# A5PSW register map
Registers from a debugger description file.
Registers are 32-bit, read-only, no defined reset value unless marked. A register's access mark holds for its fields unless they carry their own. Addresses are absolute; registers are grouped by the start of their names; lines under a group give offsets from that group; [hi:lo] are bit positions; {n}, {i} and the like mark numbered series; 'fields as' and 'values as' point back to an identical list; <NAME> marks a mode.

## A5PSW
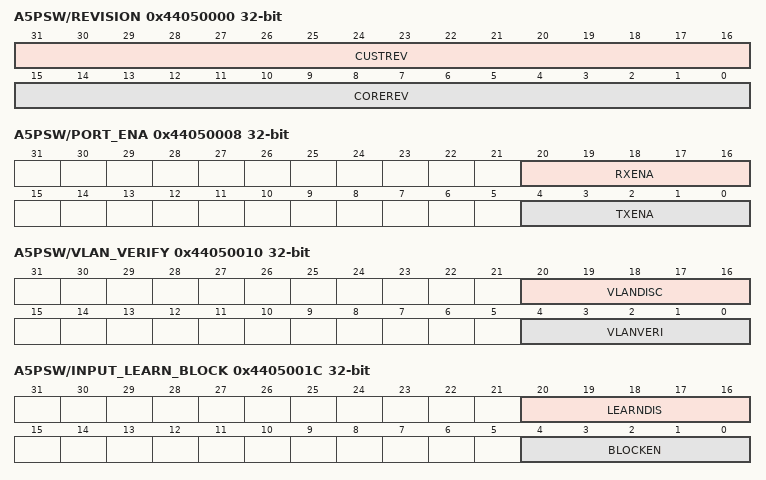
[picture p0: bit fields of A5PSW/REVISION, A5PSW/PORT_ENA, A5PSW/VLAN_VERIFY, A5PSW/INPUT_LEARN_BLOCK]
0x44050000 A5PSW/REVISION
  [31:16] CUSTREV, [15:0] COREREV
0x44050004 A5PSW/SCRATCH access not given
0x44050008 A5PSW/PORT_ENA access not given
  [20:16] RXENA, [4:0] TXENA
0x4405000C A5PSW/UCAST_DEFAULT_MASK access not given
  [4:0] UCASTDM
0x44050010 A5PSW/VLAN_VERIFY access not given
  [20:16] VLANDISC, [4:0] VLANVERI
0x44050014 A5PSW/BCAST_DEFAULT_MASK access not given
  [4:0] BCASTDM
0x44050018 A5PSW/MCAST_DEFAULT_MASK access not given
  [4:0] MCASTDM
0x4405001C A5PSW/INPUT_LEARN_BLOCK access not given
  [20:16] LEARNDIS, [4:0] BLOCKEN
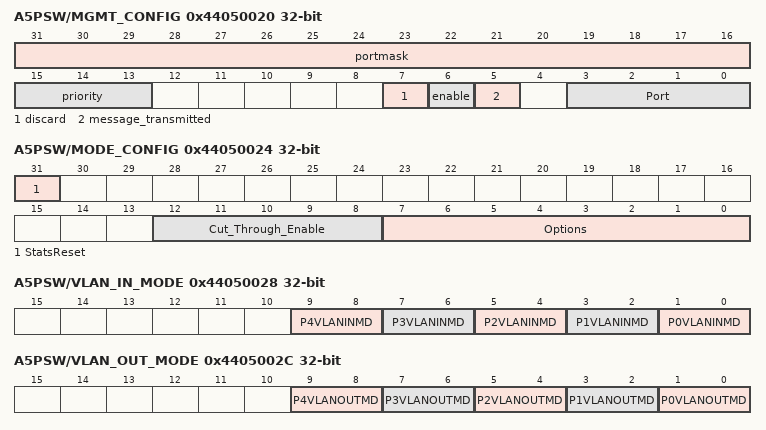
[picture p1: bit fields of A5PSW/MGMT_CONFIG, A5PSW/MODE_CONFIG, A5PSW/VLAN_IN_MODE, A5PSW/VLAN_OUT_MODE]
0x44050020 A5PSW/MGMT_CONFIG access not given
  [31:16] portmask, [15:13] priority, [7] discard, [6] enable, [5] message_transmitted, [3:0] Port
0x44050024 A5PSW/MODE_CONFIG access not given
  [31] StatsReset, [12:8] Cut_Through_Enable, [7:0] Options
0x44050028 A5PSW/VLAN_IN_MODE access not given
  [2n+1:2n] P{n}VLANINMD (n=0..4)
0x4405002C A5PSW/VLAN_OUT_MODE access not given
  [2n+1:2n] P{n}VLANOUTMD (n=0..4)
0x44050030 A5PSW/VLAN_IN_MODE_ENA access not given
  [4:0] VLANINMDEN
0x44050034 A5PSW/VLAN_TAG_ID
  [15:0] VLANTAGID
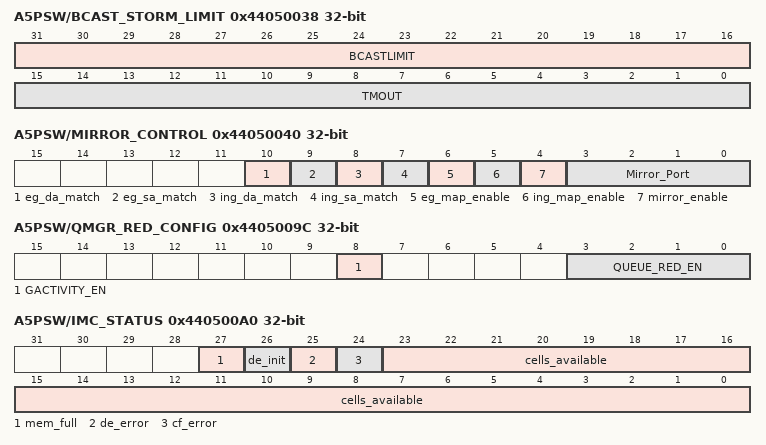
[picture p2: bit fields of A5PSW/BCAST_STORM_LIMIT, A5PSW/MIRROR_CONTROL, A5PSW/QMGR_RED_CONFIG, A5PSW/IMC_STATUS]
0x44050038 A5PSW/BCAST_STORM_LIMIT access not given
  [31:16] BCASTLIMIT, [15:0] TMOUT
0x4405003C A5PSW/MCAST_STORM_LIMIT access not given
  [31:16] MCASTLIMIT
0x44050040 A5PSW/MIRROR_CONTROL access not given
  [10] eg_da_match, [9] eg_sa_match, [8] ing_da_match, [7] ing_sa_match, [6] eg_map_enable, [5] ing_map_enable, [4] mirror_enable, [3:0] Mirror_Port
0x44050044 A5PSW/MIRROR_EG_MAP access not given
  [4:0] EMAP
0x44050048 A5PSW/MIRROR_ING_MAP access not given
  [4:0] IMAP
0x4405004C A5PSW/MIRROR_ISRC_0 access not given
  [31:0] ISRC
0x44050050 A5PSW/MIRROR_ISRC_1 access not given
  [15:0] ISRC
0x44050054 A5PSW/MIRROR_IDST_0 access not given
  [31:0] IDST
0x44050058 A5PSW/MIRROR_IDST_1 access not given
  [15:0] IDST
0x4405005C A5PSW/MIRROR_ESRC_0 access not given
  [31:0] ESRC
0x44050060 A5PSW/MIRROR_ESRC_1 access not given
  [15:0] ESRC
0x44050064 A5PSW/MIRROR_EDST_0 access not given
  [31:0] EDST
0x44050068 A5PSW/MIRROR_EDST_1 access not given
  [15:0] EDST
0x4405006C A5PSW/MIRROR_CNT access not given
  [7:0] CNT
0x44050088 A5PSW/QMGR_ST_MINCELLS access not given
  [10:0] M_CELLS_MIN
0x44050094 A5PSW/QMGR_RED_MIN4 access not given
  [31:0] CFGRED_MINTH4
0x44050098 A5PSW/QMGR_RED_MAX4 access not given
  [31:0] CFGRED_MAXTH4
0x4405009C A5PSW/QMGR_RED_CONFIG access not given
  [8] GACTIVITY_EN, [3:0] QUEUE_RED_EN
0x440500A0 A5PSW/IMC_STATUS
  [27] mem_full, [26] de_init, [25] de_error, [24] cf_error, [23:0] cells_available
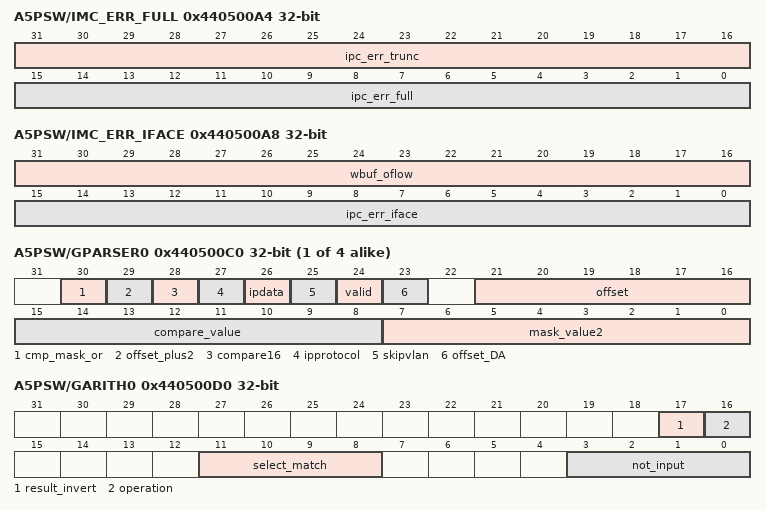
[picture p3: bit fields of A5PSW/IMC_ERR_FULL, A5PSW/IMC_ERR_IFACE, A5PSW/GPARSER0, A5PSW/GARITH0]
0x440500A4 A5PSW/IMC_ERR_FULL
  [31:16] ipc_err_trunc, [15:0] ipc_err_full
0x440500A8 A5PSW/IMC_ERR_IFACE
  [31:16] wbuf_oflow, [15:0] ipc_err_iface
0x440500AC A5PSW/IMC_ERR_QOFLOW
  [15:0] op_error
0x440500B0 A5PSW/IMC_CONFIG access not given
  [0] wfq_enable
{0x440500C0+4i} A5PSW/GPARSER{i} access not given (i=0..3)
  [30] cmp_mask_or, [29] offset_plus2, [28] compare16, [27] ipprotocol, [26] ipdata, [25] skipvlan, [24] valid, [23] offset_DA, [21:16] offset, [15:8] compare_value, [7:0] mask_value2
0x440500D0 A5PSW/GARITH0 access not given
  [17] result_invert, [16] operation, [11:8] select_match, [3:0] not_input
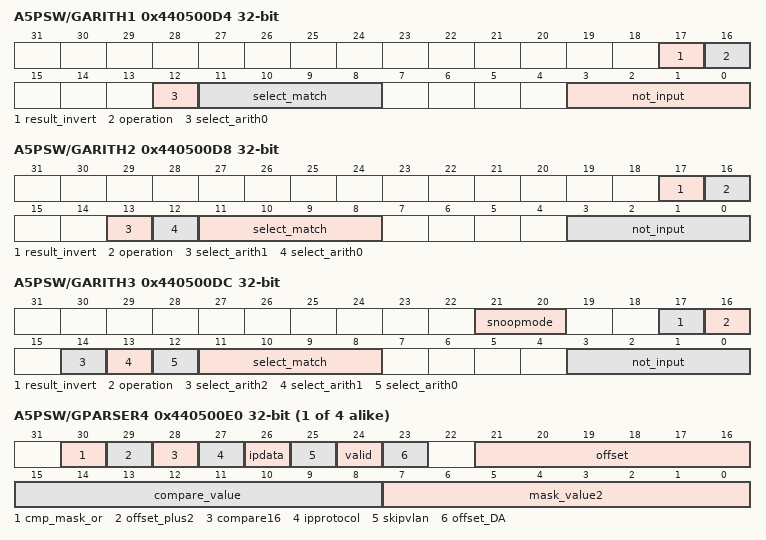
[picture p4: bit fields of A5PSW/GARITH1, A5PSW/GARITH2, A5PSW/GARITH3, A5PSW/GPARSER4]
0x440500D4 A5PSW/GARITH1 access not given
  [17] result_invert, [16] operation, [12] select_arith0, [11:8] select_match, [3:0] not_input
0x440500D8 A5PSW/GARITH2 access not given
  [17] result_invert, [16] operation, [13] select_arith1, [12] select_arith0, [11:8] select_match, [3:0] not_input
0x440500DC A5PSW/GARITH3 access not given
  [21:20] snoopmode, [17] result_invert, [16] operation, [14] select_arith2, [13] select_arith1, [12] select_arith0, [11:8] select_match, [3:0] not_input
{0x440500D0+4i} A5PSW/GPARSER{i} access not given (i=4..7)
  fields as A5PSW/GPARSER0
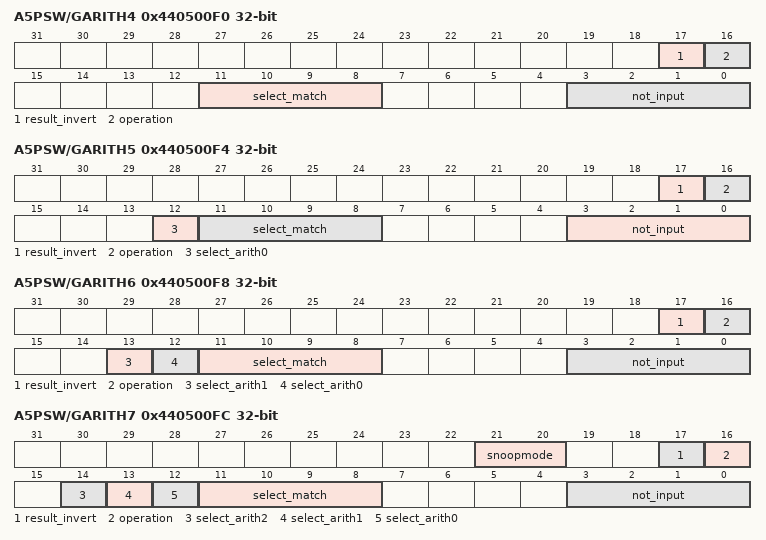
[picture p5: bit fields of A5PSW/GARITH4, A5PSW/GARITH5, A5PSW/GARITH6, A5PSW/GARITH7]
0x440500F0 A5PSW/GARITH4 access not given
  fields as A5PSW/GARITH0
0x440500F4 A5PSW/GARITH5 access not given
  fields as A5PSW/GARITH1
0x440500F8 A5PSW/GARITH6 access not given
  fields as A5PSW/GARITH2
0x440500FC A5PSW/GARITH7 access not given
  fields as A5PSW/GARITH3
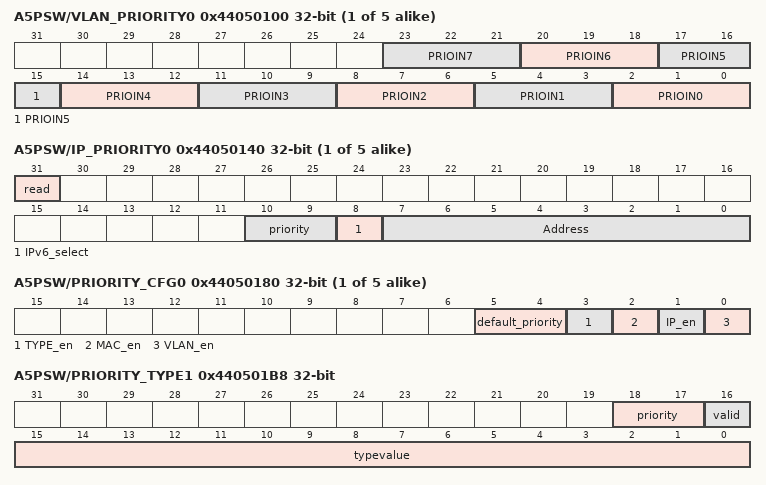
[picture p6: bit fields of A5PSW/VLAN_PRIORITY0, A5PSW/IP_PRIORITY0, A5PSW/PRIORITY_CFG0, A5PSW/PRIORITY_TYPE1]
{0x44050100+4i} A5PSW/VLAN_PRIORITY{i} access not given (i=0..4)
  [3n+2:3n] PRIOIN{n} (n=0..7)
{0x44050140+4i} A5PSW/IP_PRIORITY{i} access not given (i=0..4)
  [31] read, [10:9] priority, [8] IPv6_select, [7:0] Address
{0x44050180+4i} A5PSW/PRIORITY_CFG{i} access not given (i=0..4)
  [5:4] default_priority, [3] TYPE_en, [2] MAC_en, [1] IP_en, [0] VLAN_en
0x440501B8 A5PSW/PRIORITY_TYPE1 access not given
  [18:17] priority, [16] valid, [15:0] typevalue
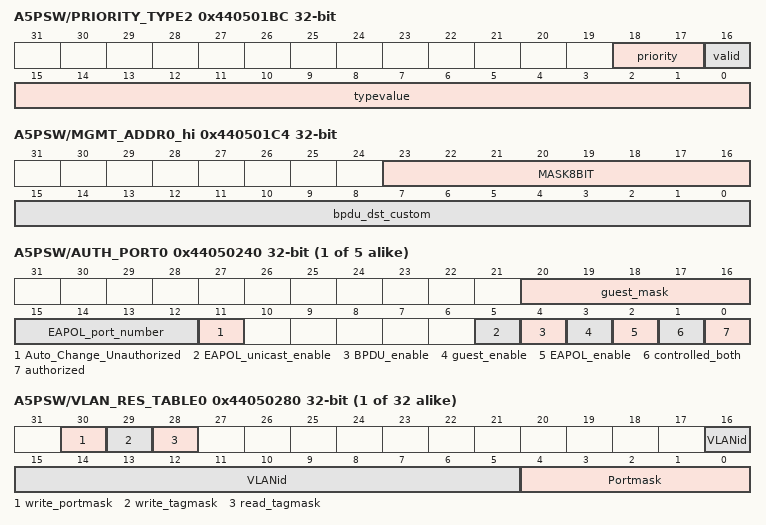
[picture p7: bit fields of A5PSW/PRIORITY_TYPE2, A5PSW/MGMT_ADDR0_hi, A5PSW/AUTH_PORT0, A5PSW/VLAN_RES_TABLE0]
0x440501BC A5PSW/PRIORITY_TYPE2 access not given
  [18:17] priority, [16] valid, [15:0] typevalue
0x440501C0 A5PSW/MGMT_ADDR0_lo access not given
  [31:0] bpdu_dst_custom
0x440501C4 A5PSW/MGMT_ADDR0_hi access not given
  [23:16] MASK8BIT, [15:0] bpdu_dst_custom
{0x44050200+4i} A5PSW/SYSTEM_TAGINFO{i} access not given (i=0..4)
  [15:0] SYSVLANINFO
{0x44050240+4i} A5PSW/AUTH_PORT{i} access not given (i=0..4)
  [20:16] guest_mask, [15:12] EAPOL_port_number, [11] Auto_Change_Unauthorized, [5] EAPOL_unicast_enable, [4] BPDU_enable, [3] guest_enable, [2] EAPOL_enable, [1] controlled_both, [0] authorized
{0x44050280+4i} A5PSW/VLAN_RES_TABLE{i} access not given (i=0..31)
  [30] write_portmask, [29] write_tagmask, [28] read_tagmask, [16:5] VLANid, [4:0] Portmask
0x44050300 A5PSW/TOTAL_DISC
0x44050304 A5PSW/TOTAL_BYT_DISC
0x44050308 A5PSW/TOTAL_FRM
0x4405030C A5PSW/TOTAL_BYT_FRM
{0x44050310+0x10*i} A5PSW/ODISC{i} (i=0..4)
{0x44050314+0x10*i} A5PSW/IDISC_VLAN{i} (i=0..4)
{0x44050318+0x10*i} A5PSW/IDISC_UNTAGGED{i} (i=0..4)
{0x4405031C+0x10*i} A5PSW/IDISC_BLOCKED{i} (i=0..4)
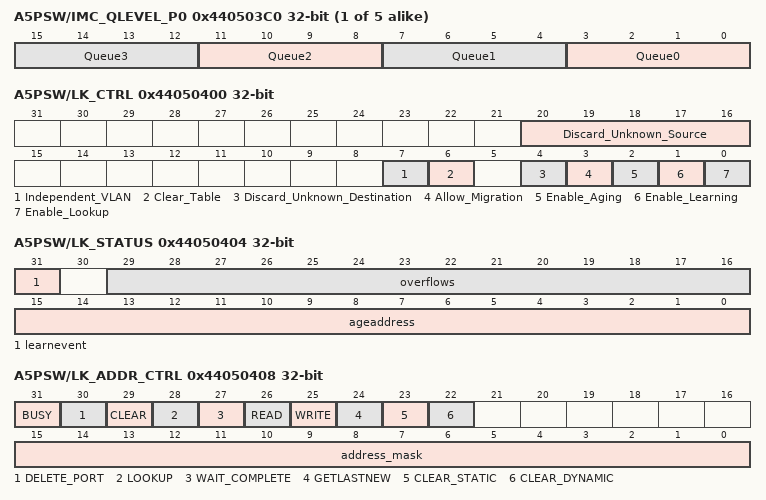
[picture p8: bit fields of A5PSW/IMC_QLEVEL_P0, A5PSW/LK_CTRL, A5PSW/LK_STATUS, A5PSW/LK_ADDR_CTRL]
{0x440503C0+4i} A5PSW/IMC_QLEVEL_P{i} (i=0..4)
  [4n+3:4n] Queue{n} (n=0..3)
0x44050400 A5PSW/LK_CTRL access not given
  [20:16] Discard_Unknown_Source, [7] Independent_VLAN, [6] Clear_Table, [4] Discard_Unknown_Destination, [3] Allow_Migration, [2] Enable_Aging, [1] Enable_Learning, [0] Enable_Lookup
0x44050404 A5PSW/LK_STATUS access not given
  [31] learnevent, [29:16] overflows, [15:0] ageaddress
0x44050408 A5PSW/LK_ADDR_CTRL access not given
  [31] BUSY, [30] DELETE_PORT, [29] CLEAR, [28] LOOKUP, [27] WAIT_COMPLETE, [26] READ, [25] WRITE, [24] GETLASTNEW, [23] CLEAR_STATIC, [22] CLEAR_DYNAMIC, [15:0] address_mask
0x4405040C A5PSW/LK_DATA_LO access not given
  [31:0] MEMDATA
0x44050410 A5PSW/LK_DATA_HI access not given
  [31:0] MEMDATA
0x44050414 A5PSW/LK_DATA_HI2 access not given
  [4:0] MEMDATA
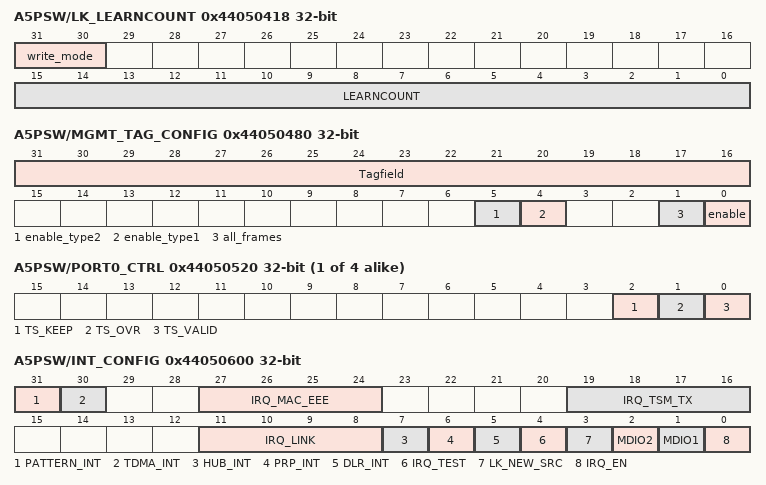
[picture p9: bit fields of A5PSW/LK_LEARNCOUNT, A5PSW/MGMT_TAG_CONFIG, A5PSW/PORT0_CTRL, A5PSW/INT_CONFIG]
0x44050418 A5PSW/LK_LEARNCOUNT access not given
  [31:30] write_mode, [15:0] LEARNCOUNT
0x4405041C A5PSW/LK_AGETIME access not given
  [23:0] LK_AGETIME
0x44050480 A5PSW/MGMT_TAG_CONFIG access not given
  [31:16] Tagfield, [5] enable_type2, [4] enable_type1, [1] all_frames, [0] enable
{0x4405050C+4i} A5PSW/PEERDELAY{i} access not given (i=0..3)
  [29:0] PEERDELAY{i}
{0x44050520+8i} A5PSW/PORT{i}_CTRL access not given (i=0..3)
  [2] TS_KEEP, [1] TS_OVR, [0] TS_VALID
{0x44050524+8i} A5PSW/PORT{i}_TIME (i=0..3)
0x44050600 A5PSW/INT_CONFIG access not given
  [31] PATTERN_INT, [30] TDMA_INT, [27:24] IRQ_MAC_EEE, [19:16] IRQ_TSM_TX, [11:8] IRQ_LINK, [7] HUB_INT, [6] PRP_INT, [5] DLR_INT, [4] IRQ_TEST, [3] LK_NEW_SRC, [2] MDIO2, [1] MDIO1, [0] IRQ_EN
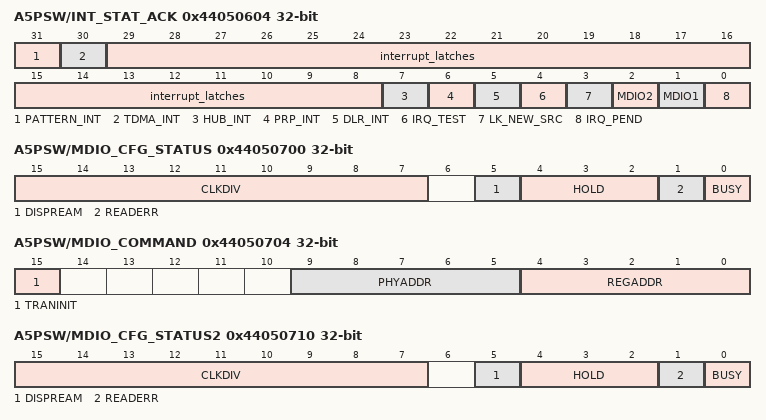
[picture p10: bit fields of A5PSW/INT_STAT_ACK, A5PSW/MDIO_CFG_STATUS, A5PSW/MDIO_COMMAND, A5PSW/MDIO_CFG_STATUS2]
0x44050604 A5PSW/INT_STAT_ACK access not given
  [31] PATTERN_INT, [30] TDMA_INT, [29:8] interrupt_latches, [7] HUB_INT, [6] PRP_INT, [5] DLR_INT, [4] IRQ_TEST, [3] LK_NEW_SRC, [2] MDIO2, [1] MDIO1, [0] IRQ_PEND
0x44050700 A5PSW/MDIO_CFG_STATUS access not given
  [15:7] CLKDIV, [5] DISPREAM, [4:2] HOLD, [1] READERR, [0] BUSY
0x44050704 A5PSW/MDIO_COMMAND access not given
  [15] TRANINIT, [9:5] PHYADDR, [4:0] REGADDR
0x44050708 A5PSW/MDIO_DATA access not given
  [15:0] MDIO_DATA
0x44050710 A5PSW/MDIO_CFG_STATUS2 access not given
  [15:7] CLKDIV, [5] DISPREAM, [4:2] HOLD, [1] READERR, [0] BUSY
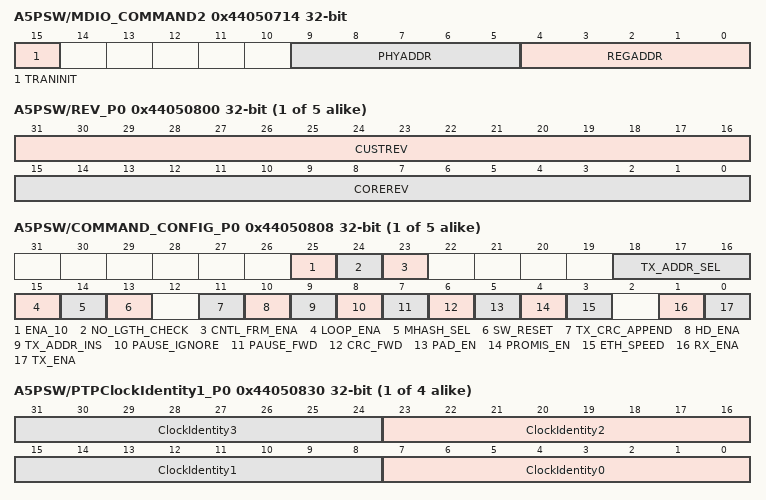
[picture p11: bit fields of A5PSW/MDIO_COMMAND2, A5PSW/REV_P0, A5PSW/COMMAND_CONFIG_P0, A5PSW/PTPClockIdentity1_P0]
0x44050714 A5PSW/MDIO_COMMAND2 access not given
  [15] TRANINIT, [9:5] PHYADDR, [4:0] REGADDR
0x44050718 A5PSW/MDIO_DATA2 access not given
  [15:0] MDIO_DATA
{0x44050800+0x400*i} A5PSW/REV_P{i} (i=0..4)
  [31:16] CUSTREV, [15:0] COREREV
{0x44050808+0x400*i} A5PSW/COMMAND_CONFIG_P{i} access not given (i=0..4)
  [25] ENA_10, [24] NO_LGTH_CHECK, [23] CNTL_FRM_ENA, [18:16] TX_ADDR_SEL, [15] LOOP_ENA, [14] MHASH_SEL, [13] SW_RESET, [11] TX_CRC_APPEND, [10] HD_ENA, [9] TX_ADDR_INS, [8] PAUSE_IGNORE, [7] PAUSE_FWD, [6] CRC_FWD, [5] PAD_EN, [4] PROMIS_EN, [3] ETH_SPEED, [1] RX_ENA, [0] TX_ENA
{0x4405080C+0x400*i} A5PSW/MAC_ADDR_0_P{i} access not given (i=0..3)
  [31:0] MAC_ADDR
{0x44050810+0x400*i} A5PSW/MAC_ADDR_1_P{i} access not given (i=0..3)
  [15:0] MAC_ADDR
{0x44050814+0x400*i} A5PSW/FRM_LENGTH_P{i} access not given (i=0..4)
  [13:0] FRM_LENGTH
{0x44050818+0x400*i} A5PSW/PAUSE_QUANT_P{i} access not given (i=0..4)
  [15:0] PAUSE_QUANT
{0x44050830+0x400*i} A5PSW/PTPClockIdentity1_P{i} access not given (i=0..3)
  [8n+7:8n] ClockIdentity{n} (n=0..3)
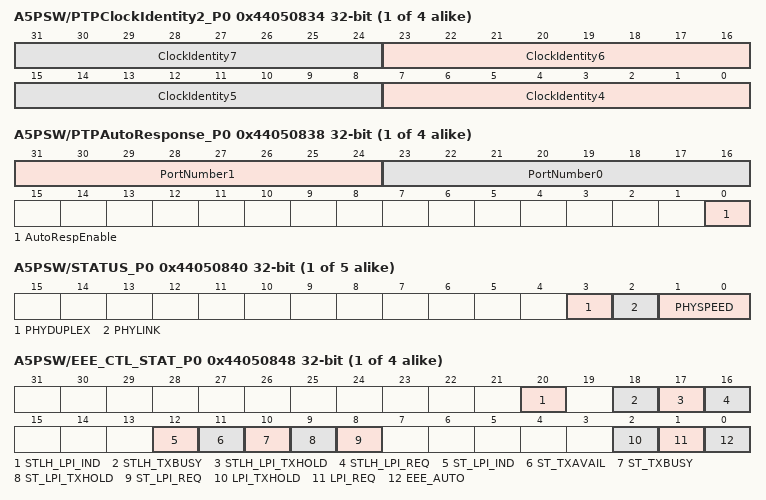
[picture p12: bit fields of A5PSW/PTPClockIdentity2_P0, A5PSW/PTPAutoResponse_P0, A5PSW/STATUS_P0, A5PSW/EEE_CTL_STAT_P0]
{0x44050834+0x400*i} A5PSW/PTPClockIdentity2_P{i} access not given (i=0..3)
  [8n-25:8n-32] ClockIdentity{n} (n=4..7)
{0x44050838+0x400*i} A5PSW/PTPAutoResponse_P{i} access not given (i=0..3)
  [31:24] PortNumber1, [23:16] PortNumber0, [0] AutoRespEnable
{0x44050840+0x400*i} A5PSW/STATUS_P{i} (i=0..4)
  [3] PHYDUPLEX, [2] PHYLINK, [1:0] PHYSPEED
{0x44050844+0x400*i} A5PSW/TX_IPG_LENGTH_P{i} access not given (i=0..4)
  [4:0] TX_IPG_LENGTH
{0x44050848+0x400*i} A5PSW/EEE_CTL_STAT_P{i} (i=0..3)
  [20] STLH_LPI_IND, [18] STLH_TXBUSY, [17] STLH_LPI_TXHOLD, [16] STLH_LPI_REQ, [12] ST_LPI_IND, [11] ST_TXAVAIL, [10] ST_TXBUSY, [9] ST_LPI_TXHOLD, [8] ST_LPI_REQ, [2] LPI_TXHOLD, [1] LPI_REQ, [0] EEE_AUTO
{0x4405084C+0x400*i} A5PSW/EEE_IDLE_TIME_P{i} access not given (i=0..3)
{0x44050850+0x400*i} A5PSW/EEE_TWSYS_TIME_P{i} access not given (i=0..3)
{0x44050854+0x400*i} A5PSW/IDLE_SLOPE_P{i} access not given (i=0..4)
  [10:0] IDLE_SLOPE
{0x44050868+0x400*i} A5PSW/aFramesTransmittedOK_P{i} (i=0..4)
{0x4405086C+0x400*i} A5PSW/aFramesReceivedOK_P{i} (i=0..4)
{0x44050870+0x400*i} A5PSW/aFrameCheckSequenceErrors_P{i} (i=0..4)
{0x44050874+0x400*i} A5PSW/aAlignmentErrors_P{i} (i=0..4)
{0x44050878+0x400*i} A5PSW/aOctetsTransmittedOK_P{i} (i=0..4)
{0x4405087C+0x400*i} A5PSW/aOctetsReceivedOK_P{i} (i=0..4)
{0x44050880+0x400*i} A5PSW/aTxPAUSEMACCtrlFrames_P{i} (i=0..4)
{0x44050884+0x400*i} A5PSW/aRxPAUSEMACCtrlFrames_P{i} (i=0..4)
{0x44050888+0x400*i} A5PSW/ifInErrors_P{i} (i=0..4)
{0x4405088C+0x400*i} A5PSW/ifOutErrors_P{i} (i=0..4)
{0x44050890+0x400*i} A5PSW/ifInUcastPkts_P{i} (i=0..4)
{0x44050894+0x400*i} A5PSW/ifInMulticastPkts_P{i} (i=0..4)
{0x44050898+0x400*i} A5PSW/ifInBroadcastPkts_P{i} (i=0..4)
{0x4405089C+0x400*i} A5PSW/ifOutDiscards_P{i} (i=0..4)
{0x440508A0+0x400*i} A5PSW/ifOutUcastPkts_P{i} (i=0..4)
{0x440508A4+0x400*i} A5PSW/ifOutMulticastPkts_P{i} (i=0..4)
{0x440508A8+0x400*i} A5PSW/ifOutBroadcastPkts_P{i} (i=0..4)
{0x440508AC+0x400*i} A5PSW/etherStatsDropEvents_P{i} (i=0..4)
{0x440508B0+0x400*i} A5PSW/etherStatsOctets_P{i} (i=0..4)
{0x440508B4+0x400*i} A5PSW/etherStatsPkts_P{i} (i=0..4)
{0x440508B8+0x400*i} A5PSW/etherStatsUndersizePkts_P{i} (i=0..4)
{0x440508BC+0x400*i} A5PSW/etherStatsOversizePkts_P{i} (i=0..4)
{0x440508C0+0x400*i} A5PSW/etherStatsPkts64Octets_P{i} (i=0..4)
{0x440508C4+0x400*i} A5PSW/etherStatsPkts65to127Octets_P{i} (i=0..4)
{0x440508C8+0x400*i} A5PSW/etherStatsPkts128to255Octets_P{i} (i=0..4)
{0x440508CC+0x400*i} A5PSW/etherStatsPkts256to511Octets_P{i} (i=0..4)
{0x440508D0+0x400*i} A5PSW/etherStatsPkts512to1023Octets_P{i} (i=0..4)
{0x440508D4+0x400*i} A5PSW/etherStatsPkts1024to1518Octets_P{i} (i=0..4)
{0x440508D8+0x400*i} A5PSW/etherStatsPkts1519toXOctets_P{i} (i=0..4)
{0x440508DC+0x400*i} A5PSW/etherStatsJabbers_P{i} (i=0..4)
{0x440508E0+0x400*i} A5PSW/etherStatsFragments_P{i} (i=0..4)
{0x440508E8+0x400*i} A5PSW/VLANReceivedOK_P{i} (i=0..4)
{0x440508F4+0x400*i} A5PSW/VLANTransmittedOK_P{i} (i=0..4)
{0x440508F8+0x400*i} A5PSW/FramesRetransmitted_P{i} (i=0..4)
{0x44050900+0x400*i} A5PSW/STATS_HIWORD_P{i} (i=0..4)
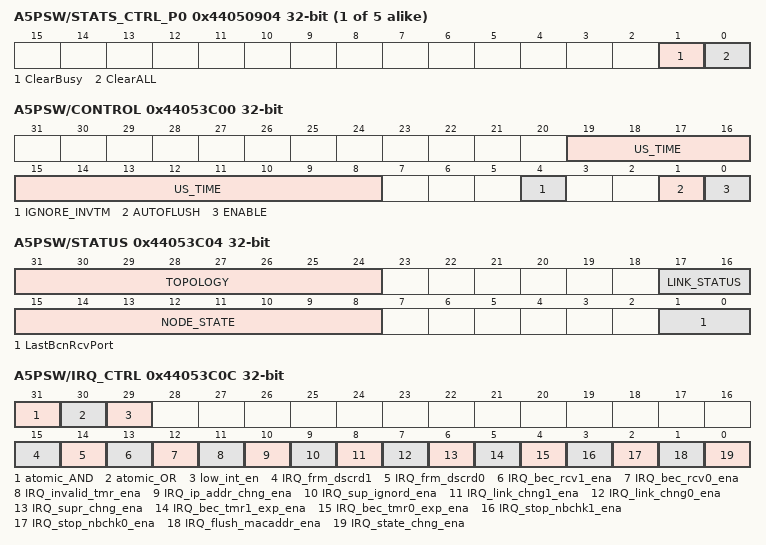
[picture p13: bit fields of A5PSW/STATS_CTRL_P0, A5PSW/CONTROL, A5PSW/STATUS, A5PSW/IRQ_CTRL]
{0x44050904+0x400*i} A5PSW/STATS_CTRL_P{i} access not given (i=0..4)
  [1] ClearBusy, [0] ClearALL
{0x44050908+0x400*i} A5PSW/STATS_CLEAR_VALUELO_P{i} (i=0..4)
{0x4405090C+0x400*i} A5PSW/STATS_CLEAR_VALUEHI_P{i} (i=0..4)
{0x44050910+0x400*i} A5PSW/aDeferred_P{i} (i=0..4)
{0x44050914+0x400*i} A5PSW/aMultipleCollisions_P{i} (i=0..4)
{0x44050918+0x400*i} A5PSW/aSingleCollisions_P{i} (i=0..4)
{0x4405091C+0x400*i} A5PSW/aLateCollisions_P{i} (i=0..4)
{0x44050920+0x400*i} A5PSW/aExcessiveCollisions_P{i} (i=0..4)
{0x44050924+0x400*i} A5PSW/aCarrierSenseErrors_P{i} (i=0..4)
0x44053C00 A5PSW/CONTROL access not given
  [19:8] US_TIME, [4] IGNORE_INVTM, [1] AUTOFLUSH, [0] ENABLE
0x44053C04 A5PSW/STATUS
  [31:24] TOPOLOGY, [17:16] LINK_STATUS, [15:8] NODE_STATE, [1:0] LastBcnRcvPort
0x44053C08 A5PSW/DLR_ETH_TYP access not given
  [15:0] DLR_ETH_TYP
0x44053C0C A5PSW/IRQ_CTRL access not given
  [31] atomic_AND, [30] atomic_OR, [29] low_int_en, [15] IRQ_frm_dscrd1, [14] IRQ_frm_dscrd0, [13] IRQ_bec_rcv1_ena, [12] IRQ_bec_rcv0_ena, [11] IRQ_invalid_tmr_ena, [10] IRQ_ip_addr_chng_ena, [9] IRQ_sup_ignord_ena, [8] IRQ_link_chng1_ena, [7] IRQ_link_chng0_ena, [6] IRQ_supr_chng_ena, [5] IRQ_bec_tmr1_exp_ena, [4] IRQ_bec_tmr0_exp_ena, [3] IRQ_stop_nbchk1_ena, [2] IRQ_stop_nbchk0_ena, [1] IRQ_flush_macaddr_ena, [0] IRQ_state_chng_ena
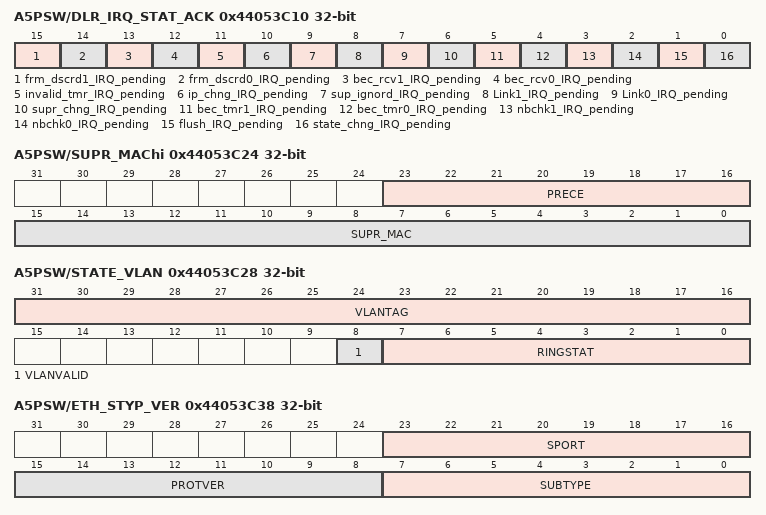
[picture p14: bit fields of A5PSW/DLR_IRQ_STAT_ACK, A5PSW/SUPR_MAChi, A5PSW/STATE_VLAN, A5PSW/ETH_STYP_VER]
0x44053C10 A5PSW/DLR_IRQ_STAT_ACK access not given
  [15] frm_dscrd1_IRQ_pending, [14] frm_dscrd0_IRQ_pending, [13] bec_rcv1_IRQ_pending, [12] bec_rcv0_IRQ_pending, [11] invalid_tmr_IRQ_pending, [10] ip_chng_IRQ_pending, [9] sup_ignord_IRQ_pending, [8] Link1_IRQ_pending, [7] Link0_IRQ_pending, [6] supr_chng_IRQ_pending, [5] bec_tmr1_IRQ_pending, [4] bec_tmr0_IRQ_pending, [3] nbchk1_IRQ_pending, [2] nbchk0_IRQ_pending, [1] flush_IRQ_pending, [0] state_chng_IRQ_pending
0x44053C14 A5PSW/LOC_MAClo access not given
  [31:0] LOC_MAC
0x44053C18 A5PSW/LOC_MAChi access not given
  [15:0] LOC_MAC
0x44053C20 A5PSW/SUPR_MAClo
  [31:0] SUPR_MAC
0x44053C24 A5PSW/SUPR_MAChi
  [23:16] PRECE, [15:0] SUPR_MAC
0x44053C28 A5PSW/STATE_VLAN
  [31:16] VLANTAG, [8] VLANVALID, [7:0] RINGSTAT
0x44053C2C A5PSW/BEC_TMOUT
0x44053C30 A5PSW/BEC_INTRVL
0x44053C34 A5PSW/SUPR_IPADR
0x44053C38 A5PSW/ETH_STYP_VER
  [23:16] SPORT, [15:8] PROTVER, [7:0] SUBTYPE
0x44053C3C A5PSW/INV_TMOUT
0x44053C40 A5PSW/SEQ_ID
0x44053C58 A5PSW/DLR_DSTlo access not given
  [31:0] DLR_DST
0x44053C5C A5PSW/DLR_DSThi access not given
  [15:0] DLR_DST
0x44053C60 A5PSW/RX_STAT0
0x44053C64 A5PSW/RX_ERR_STAT0
0x44053C68 A5PSW/TX_STAT0
0x44053C70 A5PSW/RX_STAT1
0x44053C74 A5PSW/RX_ERR_STAT1
0x44053C78 A5PSW/TX_STAT1
0x44053D00 A5PSW/PRP_CONFIG access not given
  [16] PRP_AGE_ENA, [8] TX_RCT_1588, [7] TX_RCT_UNKNOWN, [6] TX_RCT_MULTICAST, [5] TX_RCT_BROADCAST, [4:3] TX_RCT_MODE, [2] RX_REMOVE_RCT, [1] RX_DUP_ACCEPT, [0] PRP_ENA
0x44053D04 A5PSW/PRP_GROUP access not given
  [19:16] LANB_MASK, [3:0] PRP_GROUP
0x44053D08 A5PSW/PRP_SUFFIX access not given
  [15:0] PRP_SUFFIX
0x44053D0C A5PSW/PRP_LANID access not given
  [7:4] LANBID, [3:0] LANAID
0x44053D10 A5PSW/DUP_W access not given
  [8:0] DUP_W
0x44053D14 A5PSW/PRP_AGETIME access not given
  [23:0] PRP_AGETIME
0x44053D18 A5PSW/IRQ_CONTROL access not given
  [3] SEQMISSING, [2] OUTOFSEQ, [1] WRONGLAN, [0] MEMTOOLATE
0x44053D1C A5PSW/PRP_IRQ_STAT_ACK access not given
  [3:0] see_IRQ_CONTROL_register_bits
0x44053D20 A5PSW/RM_ADDR_CTRL access not given
  [31] BUSY, [29] CLEAR, [26] READ, [25] WRITE, [23] CLEAR_MEMORY, [22] CLEAR_DYNAMIC, [15:0] address
0x44053D24 A5PSW/RM_DATA access not given
0x44053D2C A5PSW/RM_STATUS
  [15:0] ageaddress
0x44053D30 A5PSW/TxSeqTooLate access not given
0x44053D34 A5PSW/CntErrWrongLanA
0x44053D38 A5PSW/CntErrWrongLanB
0x44053D3C A5PSW/CntDupLanA
0x44053D40 A5PSW/CntDupLanB
0x44053D44 A5PSW/CntOutOfSeqLowA
0x44053D48 A5PSW/CntOutOfSeqLowB
0x44053D4C A5PSW/CntOutOfSeqA
0x44053D50 A5PSW/CntOutOfSeqB
0x44053D54 A5PSW/CntAcceptA
0x44053D58 A5PSW/CntAcceptB
0x44053D5C A5PSW/CntMissing
0x44053E00 A5PSW/HUB_CONFIG access not given
  [3] HUB_ISOLATE, [2] TRIGGER_MODE, [1] RETRANSMIT_ENA, [0] HUB_ENA
0x44053E04 A5PSW/HUB_GROUP access not given
  [3:0] HUB_GROUP
0x44053E08 A5PSW/HUB_DEFPORT access not given
  [3:0] HUB_DEFPORT
0x44053E0C A5PSW/HUB_TRIGGER_IMMEDIATE access not given
  [3:0] HUB_TRIGGER_IMMEDIATE
0x44053E10 A5PSW/HUB_TRIGGER_AT access not given
  [3:0] HUB_TRIGGER_AT
0x44053E14 A5PSW/HUB_TTIME access not given
0x44053E18 A5PSW/HUB_IRQ_CONTROL access not given
  [6] TRIGGER_TIMER_ACK, [5] TRIGGER_IMMEDIATE_ACK, [4] CHANGE_DET, [3:0] RX_TRIGGER
0x44053E1C A5PSW/HUB_IRQ_STAT_ACK access not given
  [6:0] INT_PEND
0x44053E20 A5PSW/HUB_STATUS
  [12] TX_Change_Pending, [11] Speed_OK, [10] TX_BUSY, [9] TX_ACTIVE, [3:0] PORTS_ACTIVE
0x44053E24 A5PSW/HUB_OPORT_STATUS
  [3:0] HUB_OPORT_STATUS
{0x44053E80+4i} A5PSW/RXMATCH_CONFIG{i} access not given (i=0..4)
  [7:0] PATTERN_EN
{0x44053EB0+4i} A5PSW/PATTERN_CTRL{i} access not given (i=0..7)
  [20:16] PORTMASK, [13:12] PRIORITY, [8] HUBTRIGGER, [3] SET_PRIO, [2] DISCARD, [1] MGMTFWD, [0] MATCH_NOT
0x44053ED0 A5PSW/PTN_IRQ_CONTROL access not given
  [7:0] MATCHINT
0x44053ED4 A5PSW/PTN_IRQ_STAT_ACK access not given
  [7:0] MATCHINT
0x44053EDC A5PSW/PATTERN_SEL access not given
  [2:0] PATTERN_SEL
0x44053EE0 A5PSW/PTRN_CMP_30 access not given
0x44053EE4 A5PSW/PTRN_CMP_74 access not given
0x44053EE8 A5PSW/PTRN_CMP_118 access not given
0x44053EF0 A5PSW/PTRN_MSK_30 access not given
0x44053EF4 A5PSW/PTRN_MSK_74 access not given
0x44053EF8 A5PSW/PTRN_MSK_118 access not given
0x44053F00 A5PSW/TDMA_CONFIG access not given
  [1] WAIT_START, [0] TDMA_ENA
0x44053F04 A5PSW/TDMA_PORTS access not given
  [n] port{n} (n=0..3)
0x44053F08 A5PSW/TDMA_START access not given
0x44053F0C A5PSW/TDMA_MODULO access not given
0x44053F10 A5PSW/TDMA_CYCLE access not given
{0x44053F10+4i} A5PSW/TDMA_T{i} access not given (i=1..3)
0x44053F20 A5PSW/QUEUES_TS access not given
  [n] queue{n} (n=0..3)
{0x44053F20+4i} A5PSW/QUEUES_T{i} access not given (i=1..3)
  [n] queue{n} (n=0..3)
0x44053F30 A5PSW/QUEUES_START access not given
  [n] queue{n} (n=0..3)
0x44053F34 A5PSW/TIME_LOAD_NEXT
0x44053F38 A5PSW/TDMA_IRQ_CONTROL access not given
  [3] T3_EN, [2] T2_EN, [1] T1_EN, [0] CYCLE_EN
0x44053F3C A5PSW/TDMA_IRQ_STAT_ACK access not given
  [3] T3_EN, [2] T2_EN, [1] T1_EN, [0] CYCLE_EN
